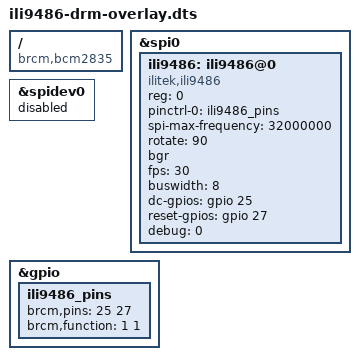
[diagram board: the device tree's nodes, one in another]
/dts-v1/;
/plugin/;

/ {
	compatible = "brcm,bcm2835";

	fragment@0 {
		target = <&spi0>;
		__overlay__ {
			status = "okay";
		};
	};

	fragment@1 {
		target = <&spidev0>;
		__overlay__ {
			status = "disabled";
		};
	};

	fragment@2 {
		target = <&gpio>;
		__overlay__ {
			ili9486_pins: ili9486_pins {
				brcm,pins = <25 27>;
				brcm,function = <1 1>; /* out */
			};
		};
	};

	fragment@3 {
		target = <&spi0>;
		__overlay__ {
			/* avoid dtc warning */
			#address-cells = <1>;
			#size-cells = <0>;

			ili9486: ili9486@0 {
				compatible = "ilitek,ili9486";
				reg = <0>;
				pinctrl-names = "default";
				pinctrl-0 = <&ili9486_pins>;

				spi-max-frequency = <32000000>;
				rotate = <90>;
				bgr;
				fps = <30>;
				buswidth = <8>;
				dc-gpios = <&gpio 25 0>;
				reset-gpios = <&gpio 27 0>;
				debug = <0>;
			};
		};
	};

	__overrides__ {
		speed =     <&ili9486>,"spi-max-frequency:0";
		rotate =    <&ili9486>,"rotate:0";
		fps =       <&ili9486>,"fps:0";
		debug =     <&ili9486>,"debug:0";
		dc_pin =    <&ili9486>,"dc-gpios:4",
		            <&ili9486_pins>,"brcm,pins:0";
		reset_pin = <&ili9486>,"reset-gpios:4",
		            <&ili9486_pins>,"brcm,pins:4";
	};
};
